# nrf7140_secure register map
Vendor: Nordic Semiconductor; Series: nRF71; File version: 1
CPU: CM33 r0p4, little endian, MPU, no FPU, 3 interrupt priority bits, 480 interrupts, 8 SAU regions
Registers are 32-bit, read-write, reset 0x0 unless marked. A register's access mark holds for its fields unless they carry their own. Offsets are from the block's base; [hi:lo] are bit positions; lines under a group give offsets from that group; {n}, {i} and the like mark numbered series; 'fields as' and 'values as' point back to an identical list.

## GLOBAL_RAMC122_NS — RAM Controller 0
Base 0x4F8DA000
Same registers: GLOBAL_RAMC123_NS 0x4F8DD000, GLOBAL_RAMC122_S 0x5F8DA000, GLOBAL_RAMC123_S 0x5F8DD000
0x500 WAITSTATES — Waitstates for read operations.
  [0] WAITSTATES — Number of waitstates for a read from the RAM.

## GLOBAL_DPPIC120_NS — Distributed programmable peripheral interconnect controller 0
Base 0x4F8E1000
Same registers: GLOBAL_DPPIC130_NS 0x4F922000, GLOBAL_DPPIC131_NS 0x4F981000, GLOBAL_DPPIC132_NS 0x4F991000, GLOBAL_DPPIC133_NS 0x4F9A1000, GLOBAL_DPPIC134_NS 0x4F9B1000, GLOBAL_DPPIC135_NS 0x4F9C1000, GLOBAL_DPPIC136_NS 0x4F9D1000, GLOBAL_DPPIC120_S 0x5F8E1000, GLOBAL_DPPIC130_S 0x5F922000, GLOBAL_DPPIC131_S 0x5F981000, GLOBAL_DPPIC132_S 0x5F991000, GLOBAL_DPPIC133_S 0x5F9A1000, GLOBAL_DPPIC134_S 0x5F9B1000, GLOBAL_DPPIC135_S 0x5F9C1000, GLOBAL_DPPIC136_S 0x5F9D1000
{0x0+8i} TASKS_CHG[{i}] (i=0..3) group — Channel group tasks
  0x00 EN wo — Description cluster: Enable channel group n
    [0] EN — Enable channel group n
      1=Trigger task
  0x04 DIS wo — Description cluster: Disable channel group n
    [0] DIS — Disable channel group n
      1=Trigger task
{0x80+8i} SUBSCRIBE_CHG[{i}] (i=0..3) group — Subscribe configuration for tasks
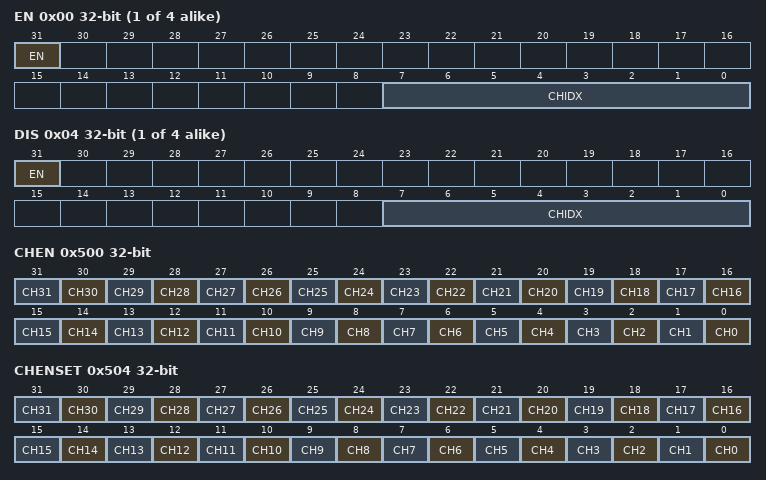
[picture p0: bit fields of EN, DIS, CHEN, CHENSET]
  0x00 EN — Description cluster: Subscribe configuration for task CHG[n].EN
    [31] EN
      0=Disabled (Disable subscription); 1=Enabled (Enable subscription)
    [7:0] CHIDX — DPPI channel that task CHG[n].EN will subscribe to
  0x04 DIS — Description cluster: Subscribe configuration for task CHG[n].DIS
    [31] EN
      values as SUBSCRIBE_CHG[0].EN.EN
    [7:0] CHIDX — DPPI channel that task CHG[n].DIS will subscribe to
0x500 CHEN — Channel enable register
  [all] fields
    0=Disabled (Disable channel); 1=Enabled (Enable channel)
  [n] CH{n} (n=0..31) — Enable or disable channel {n}
0x504 CHENSET write-1-sets — Channel enable set register
  [all] fields
    on read: 0=Disabled (Read: Channel disabled); 1=Enabled (Read: Channel enabled) | on write: 1=Set (Write: Enable channel)
  [n] CH{n} (n=0..31) — Channel {n} enable set register. Writing 0 has no effect.
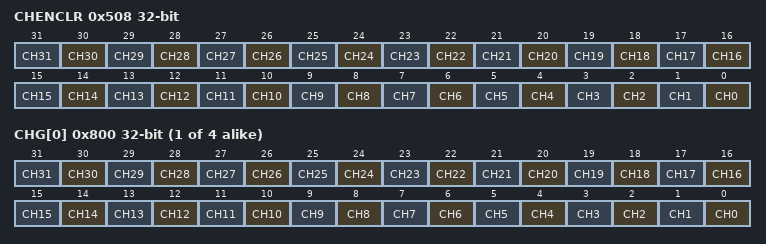
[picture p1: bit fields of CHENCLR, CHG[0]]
0x508 CHENCLR write-1-clears — Channel enable clear register
  [all] fields
    on read: 0=Disabled (Read: Channel disabled); 1=Enabled (Read: Channel enabled) | on write: 1=Clear (Write: Disable channel)
  [n] CH{n} (n=0..31) — Channel {n} enable clear register. Writing 0 has no effect.
{0x800+4i} CHG[{i}] (i=0..3) — Description collection: Channel group n Note: Writes to this register are ignored if either SUBSCRIBE_CHG[n].EN or SUBSCRIBE_CHG[n].DIS is enabled
  [all] fields
    0=Excluded; 1=Included
  [n] CH{n} (n=0..31) — Include or exclude channel {n}

## IPCMAP_S — IPCMAP APB registers
Base 0x5F923000
{0x400+8i} CHANNEL[{i}] (i=0..15) group — Unspecified
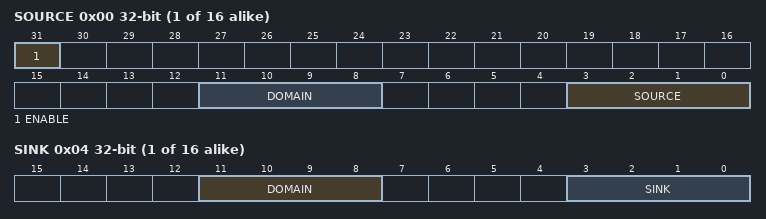
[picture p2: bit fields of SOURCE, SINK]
  0x00 SOURCE — Description cluster: The IPCT source configuration for the channel [n] from a ICPT.
    [31] ENABLE — Channel enable.
      0=Disabled (Disable channel.); 1=Enabled (Enable channel.)
    [11:8] DOMAIN — Domain identifier.
    [3:0] SOURCE — Source identification for IPC mapping.
  0x04 SINK — Description cluster: The IPCT sink configuration for the channel [n] to another ICPT.
    [11:8] DOMAIN — Domain identifier.
    [3:0] SINK — Sink identifiation for IPC mapping.

## IRQMAP_S — IRQMAP APB registers
Base 0x5F924000
{0x400+4i} IRQ[{i}] (i=0..479) group — Unspecified
  0x00 SINK — Description cluster: The interrupt sink configuration for interrupt [n] to a processor.
    [11:8] PROCESSORID — Processor identifier.
